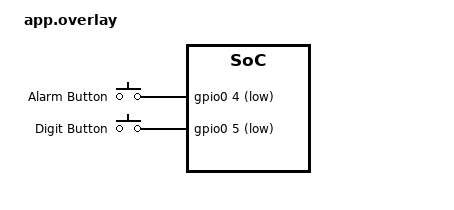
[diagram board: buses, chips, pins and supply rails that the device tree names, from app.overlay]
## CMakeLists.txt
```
# SPDX-License-Identifier: Apache-2.0
cmake_minimum_required(VERSION 3.20.0)

# Define a flag we can pass from the command line (defaults to OFF)
option(BUILD_UNIT_TESTS "Build the host-based unit tests instead of firmware" OFF)

if(BUILD_UNIT_TESTS)
    # ==============================================================
    # HOST UNIT TEST BUILD
    # ==============================================================
    project(display_tests)
    
    # Create a standard desktop executable
    add_executable(unit_test_app 
        test/test_main.c 
        test/mock_os_abstraction.c
        test/mock_display_driver.c
        src/state_manager.c 
        src/display_manager.c
    )
    
    # Point it to your standard headers
    target_include_directories(unit_test_app PRIVATE include)

else()
    # ==============================================================
    # ZEPHYR FIRMWARE BUILD
    # ==============================================================
    find_package(Zephyr REQUIRED HINTS $ENV{ZEPHYR_BASE})
    project(minimal)

    zephyr_include_directories(include)

    target_sources(app PRIVATE 
        src/main.c 
        src/state_manager.c 
        src/display_manager.c 
        src/button_listener.c
        src/zephyr/os_abstraction_zephyr.c
        src/zephyr/zephyr_display_driver.c 
        src/zephyr/zephyr_button_driver.c    
    )
endif()
```

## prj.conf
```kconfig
CONFIG_SAMPLE_DO_OUTPUT=y
CONFIG_SHELL=y
CONFIG_I2C=y
CONFIG_I2C_SHELL=y
CONFIG_I2C_LOG_LEVEL_DBG=y
```

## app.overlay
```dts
/ {
    aliases {
        alarm-button = &button_alarm;
        digit-button = &button_digit;
    };

    gpio_keys {
        compatible = "gpio-keys";
        
        button_alarm: button_alarm {
            /* GPIO 4, enable internal pull-up,
               and treat LOW as logically active */
            gpios = <&gpio0 4 (GPIO_PULL_UP | GPIO_ACTIVE_LOW)>;
            label = "Alarm Button";
        };

        button_digit: button_digit {
            /* GPIO 5, enable internal pull-up,
               and treat LOW as logically active */
            gpios = <&gpio0 5 (GPIO_PULL_UP | GPIO_ACTIVE_LOW)>;
            label = "Digit Button";
        };
    };
};
```

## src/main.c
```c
/*
 * Copyright (c) 2019 Nordic Semiconductor ASA
 *
 * SPDX-License-Identifier: Apache-2.0
 */

#include <stdio.h>
#include <zephyr/kernel.h>
#include "state_manager.h"
#include "display_manager.h"
#include "button_listener.h"
#include "os_abstraction.h"

// The function the OS will call every time the timer expires
void system_tick_callback(void)
{
    StateMsg_t msg;
    msg.event = EVENT_SYS_TICK_MINUTE;
    
    // Drop the event into the queue.
    // (In a real Zephyr/FreeRTOS implementation behind your OSAL, this 
    // underlying queue send needs to have a timeout of 0 / K_NO_WAIT 
    // so it doesn't block the OS timer daemon!)
    rtos_queue_send(state_message_queue, &msg);
}

int main(void)
{
    //Iniitalize message queues here
    printf("Initializing queues.\n");
    state_message_queue = rtos_queue_create(10, sizeof(StateMsg_t));
    display_message_queue = rtos_queue_create(10, sizeof(DisplayMsg_t));
    
    // Create and initialize tasks
    printf("Starting tasks.\n");
    rtos_thread_create(display_manager_task, "DisplayManagerTask",
		       1024, TASK_PRIORITY_MEDIUM);
    rtos_thread_create(button_listener_task, "ButtonListenerTask",
		       1024, TASK_PRIORITY_MEDIUM);
    rtos_thread_create(state_manager_task, "StateManagerTask",
		       1024, TASK_PRIORITY_MEDIUM);

    printf("Setting \"minute change\" timer...\n");    
    // Create a timer that fires every 60,000 ms (1 minute) and repeats (true)
    RtosTimerHandle_t minute_timer = rtos_timer_create(
        "SysTickTimer", 
        60000, 
        true, 
        system_tick_callback
    );
    
    // Start the timer ticking
    rtos_timer_start(minute_timer);    

    // This must be at the end, since it blocks forever
    rtos_start_scheduler();        
    return 0;
}
```

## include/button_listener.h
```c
#ifndef BUTTON_LISTENER_H
#define BUTTON_LISTENER_H

// Button listener task entry point
extern void button_listener_task(void);

#endif // BUTTON_LISTENER_H
```

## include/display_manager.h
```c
#ifndef DISPLAY_MANAGER_H
#define DISPLAY_MANAGER_H

#include <stdint.h>
#include <stdbool.h>

#include "os_abstraction.h"

typedef enum {
    VIEW_STATE_TIME,
    VIEW_STATE_ALARM,
    VIEW_STATE_DIGIT
} DisplayViewState_t;


typedef enum {
    DISPLAY_EVENT_UPDATE_TIME,
    DISPLAY_EVENT_UPDATE_ALARM_STATE,
    DISPLAY_EVENT_SET_ACTIVE_VIEW
} DisplayEvent_t;

// Message structure sent by the higher-level State Manager
typedef struct {
    DisplayEvent_t event;
    union {
        struct { uint8_t hours; uint8_t minutes; } time;
        struct { bool is_set; uint8_t hours; uint8_t minutes; } alarm;
        struct { DisplayViewState_t view; uint8_t digit_val; } view_ctrl;
    } payload;
} DisplayMsg_t;

extern RtosQueueHandle_t display_message_queue;

// Display manager task entry point
extern void initialize_display_manager(void);
extern void display_manager_task();
extern void display_manager_process_event(DisplayMsg_t *);

#endif // DISPLAY_MANAGER_H
```

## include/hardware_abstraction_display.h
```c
#include <stdbool.h>

// Clears the entire dot matrix display
extern void disp_hw_clear(void);

// Writes a formatted string to the dot matrix display (e.g., "12:30", "--:--")
extern void disp_hw_write_text(const char* text);

// Controls the specific hardware pixel in the upper right corner
extern void disp_hw_set_upper_right_dot(bool enable);
```

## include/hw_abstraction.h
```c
#ifndef HW_ABSTRACTION_H
#define HW_ABSTRACTION_H

#include <stdbool.h>
#include "os_abstraction.h"

// Clears the entire dot matrix display
extern void disp_hw_clear(void);

// Writes a formatted string to the dot matrix display (e.g., "12:30", "--:--")
extern void disp_hw_write_text(const char* text);

// Controls the specific hardware pixel in the upper right corner
extern void disp_hw_set_upper_right_dot(bool enable);

// Reads the physical state of the buttons (true = pressed, false = released)
extern RtosSemaphoreHandle_t hw_btn_semaphore_setup(void);
extern bool hw_btn_read_alarm(void);
extern bool hw_btn_read_digit(void);

#endif // HW_ABSTRACTION_H
```

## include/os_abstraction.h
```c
#ifndef OS_ABSTRACTION_H
#define OS_ABSTRACTION_H

#include <stdint.h>
#include <stdbool.h>

#define RTOS_WAIT_FOREVER 0xFFFFFFFF

/*** Time and Timers ***/
// Timer primitives
typedef void* RtosTimerHandle_t;
typedef void (*RtosTimerCallback_t)(void);

// Need to be sure to trigger this callback from a timer
extern void minute_tick_callback(void);

// Returns current system ticks in milliseconds
extern uint32_t rtos_get_time_ms(void);

// RTOS delay (OS sleep, not a busy wait)
extern void rtos_delay_ms(uint32_t ms);


/*** Queues ***/
typedef void* RtosQueueHandle_t;

extern bool rtos_queue_receive(RtosQueueHandle_t queue,
			       void* buffer, uint32_t timeout_ms);
extern bool rtos_queue_send(RtosQueueHandle_t queue, void* data);


/*** Semaphores ***/
typedef void* RtosSemaphoreHandle_t;

extern void rtos_semaphore_wait(RtosSemaphoreHandle_t semaphore,
				uint32_t timeout_ms);


// Initializes all OS primitives (queues, semaphores, timers) and spawns tasks
extern void rtos_system_init(void);

#endif // OS_ABSTRACTION_H
```

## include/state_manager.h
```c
#ifndef STATE_MANAGER_H
#define STATE_MANAGER_H

#include <stdint.h>
#include <stdbool.h>
#include "os_abstraction.h"

// System events generated by the hardware layer (Buttons, Timers) and handled by the state manager
typedef enum {
    EVENT_BUTTON_ALARM_PRESSED,
    EVENT_BUTTON_ALARM_RELEASED,
    EVENT_BUTTON_DIGIT_PRESSED,
    EVENT_BUTTON_DIGIT_RELEASED,
    EVENT_SYS_TICK_MINUTE
} StateEvent_t;

typedef struct {
    StateEvent_t event;
} StateMsg_t;


extern RtosQueueHandle_t state_message_queue;

// Main state manager task entry point
extern void initialize_state_manager(void);
extern void state_manager_task(void);
extern void state_manager_process_event(StateMsg_t *msg);

#endif // STATE_MANAGER_H
```

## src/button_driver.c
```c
#include <stdio.h>
#include "hw_abstraction.h"

bool hw_btn_read_alarm(void)
{
    // Mock implementation
    return false;
}

bool hw_btn_read_digit(void)
{
    // Mock implementation
    return false; 
}
```

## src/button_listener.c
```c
#include <stddef.h>
#include <stdio.h>
#include "button_listener.h"
#include "state_manager.h"
#include "hw_abstraction.h"

void button_listener_task(void)
{
    StateMsg_t msg;
    
    bool last_alarm_state = false;
    bool last_digit_state = false;

    RtosSemaphoreHandle_t hw_btn_isr_semaphore
	= hw_btn_semaphore_setup();
   
    if (hw_btn_isr_semaphore == NULL) {
	printf("Problem setting up button semaphore\n");
	return;
    }

    while (1) {
        // 1. Sleep entirely until the actual hardware ISR gives this semaphore
        rtos_semaphore_wait(hw_btn_isr_semaphore, RTOS_WAIT_FOREVER);

        // 2. Debounce: Wait 20ms for the physical switch contacts to settle
        rtos_delay_ms(20);

        // 3. Read the stable hardware states
        bool current_alarm_state = hw_btn_read_alarm();
        bool current_digit_state = hw_btn_read_digit();

        // 4. Compare to previous state and emit events ONLY on state changes
        if (current_alarm_state != last_alarm_state) {
            msg.event = current_alarm_state ? EVENT_BUTTON_ALARM_PRESSED : EVENT_BUTTON_ALARM_RELEASED;
            rtos_queue_send(state_message_queue, &msg);
            last_alarm_state = current_alarm_state;
        }

        if (current_digit_state != last_digit_state) {
            msg.event = current_digit_state ? EVENT_BUTTON_DIGIT_PRESSED : EVENT_BUTTON_DIGIT_RELEASED;
            rtos_queue_send(state_message_queue, &msg);
            last_digit_state = current_digit_state;
        }
    }
    return;
}
```

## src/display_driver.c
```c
#include <stdio.h>
#include "hw_abstraction.h"

void disp_hw_clear(void)
{
    printf("Calling disp_hw_clear()\n"); 
}

void disp_hw_write_text(const char* text)
{
    printf("Calling disp_hw_write_text(text=\"%s\")\n", text); 
}

void disp_hw_set_upper_right_dot(bool enable)
{
    printf("disp_hw_set_upper_right_dot(enable=\"%s\")\n",
	   enable ? "true" : "false"); 
}
```

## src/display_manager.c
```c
#include <stdio.h>
#include <string.h>
#include "display_manager.h"
#include "os_abstraction.h"
#include "hw_abstraction.h"

static struct {
    DisplayViewState_t current_view;
    
    uint8_t current_hours;
    uint8_t current_minutes;
    
    bool alarm_is_set;
    uint8_t alarm_hours;
    uint8_t alarm_minutes;
    
    uint8_t temp_digit;
} display_manager_context;


// Helper function to render the current state to the hardware
static void render_display(void)
{
    char render_buffer[8]; // Enough to hold "HH:MM" + null terminator
    
    disp_hw_clear();

    switch (display_manager_context.current_view) {
        case VIEW_STATE_TIME:
            snprintf(render_buffer, sizeof(render_buffer), "%02d:%02d",
		     display_manager_context.current_hours, display_manager_context.current_minutes);
            disp_hw_write_text(render_buffer);
            break;

        case VIEW_STATE_ALARM:
            if (display_manager_context.alarm_is_set) {
                snprintf(render_buffer, sizeof(render_buffer), "%02d:%02d",
			 display_manager_context.alarm_hours, display_manager_context.alarm_minutes);
            } else {
                snprintf(render_buffer, sizeof(render_buffer), "--:--");
            }
            disp_hw_write_text(render_buffer);
            break;

        case VIEW_STATE_DIGIT:
            snprintf(render_buffer, sizeof(render_buffer), "%d", display_manager_context.temp_digit);
            disp_hw_write_text(render_buffer);
            break;
    }

    // The alarm indicator dot is persistently rendered regardless of the current view
    disp_hw_set_upper_right_dot(display_manager_context.alarm_is_set);
}

void display_manager_process_event(DisplayMsg_t *msg)
{
    // Process incoming message from higher-level state manager
    switch (msg->event) {
    case DISPLAY_EVENT_UPDATE_TIME:
	display_manager_context.current_hours = msg->payload.time.hours;
	display_manager_context.current_minutes = msg->payload.time.minutes;
	break;

    case DISPLAY_EVENT_UPDATE_ALARM_STATE:
	display_manager_context.alarm_is_set = msg->payload.alarm.is_set;
	display_manager_context.alarm_hours = msg->payload.alarm.hours;
	display_manager_context.alarm_minutes = msg->payload.alarm.minutes;
	break;

    case DISPLAY_EVENT_SET_ACTIVE_VIEW:
	display_manager_context.current_view = msg->payload.view_ctrl.view;
	display_manager_context.temp_digit = msg->payload.view_ctrl.digit_val;
	break;
    }

    render_display();
}

void initialize_display_manager(void)
{
    memset(&display_manager_context, 0, sizeof(display_manager_context));
    display_manager_context.current_view = VIEW_STATE_TIME;
    render_display();
}

void display_manager_task(void)
{
    DisplayMsg_t msg;

    // Initialize state
    initialize_display_manager();
    
    while (1) {
        // Wait indefinitely for a message.
        if (rtos_queue_receive(display_message_queue, &msg, RTOS_WAIT_FOREVER)) {
            display_manager_process_event(&msg);
	}
    }
}
```

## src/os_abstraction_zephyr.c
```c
#include <stdio.h>
#include <zephyr/kernel.h>
#include "os_abstraction.h"
#include "state_manager.h"
#include "display_manager.h"
#include "button_listener.h"

/* ========================================================================= *
 * Static Allocations (Zephyr Macros)
 * ========================================================================= */

// 1. Queues
K_MSGQ_DEFINE(z_state_msgq, sizeof(StateMsg_t), 10, 4);
K_MSGQ_DEFINE(z_display_msgq, sizeof(DisplayMsg_t), 10, 4);

// Map the static Zephyr objects to the abstract global handles expected by the app
RtosQueueHandle_t state_message_queue = &z_state_msgq;

RtosQueueHandle_t display_message_queue = &z_display_msgq;

// 2. Threads (Auto-started by Zephyr before main)
// K_THREAD_DEFINE(name, stack_size, entry_fn, p1, p2, p3, prio, options, delay)
K_THREAD_DEFINE(display_tid, 1024, display_manager_task, NULL, NULL, NULL, 5, 0, 0);
K_THREAD_DEFINE(button_tid,  1024, button_listener_task, NULL, NULL, NULL, 5, 0, 0);
K_THREAD_DEFINE(state_tid,   1024, state_manager_task,   NULL, NULL, NULL, 5, 0, 0);

// 3. System Timer
extern void minute_tick_callback(void); // Declared in main.c
K_TIMER_DEFINE(z_sys_timer, (k_timer_expiry_t)minute_tick_callback, NULL);


/* ========================================================================= *
 * Initialization and Scheduler
 * ========================================================================= */

void rtos_system_init(void)
{
    printf("OSAL: Starting system timer...\n");
    // Start the static timer (60 seconds duration, 60 seconds period)
    k_timer_start(&z_sys_timer, K_MSEC(60000), K_MSEC(60000));

    k_sleep(K_FOREVER);
}

/* ========================================================================= *
 * OS API Implementations
 * ========================================================================= */

uint32_t rtos_get_time_ms(void) {
    return k_uptime_get_32();
}

void rtos_delay_ms(uint32_t ms) {
    k_msleep(ms);
}

bool rtos_queue_receive(RtosQueueHandle_t queue, void* buffer, uint32_t timeout_ms) {
    struct k_msgq *q = (struct k_msgq *)queue;
    k_timeout_t z_timeout = (timeout_ms == RTOS_WAIT_FOREVER) ? K_FOREVER : K_MSEC(timeout_ms);
    return (k_msgq_get(q, buffer, z_timeout) == 0);
}

bool rtos_queue_send(RtosQueueHandle_t queue, void* data) {
    struct k_msgq *q = (struct k_msgq *)queue;
    return (k_msgq_put(q, data, K_NO_WAIT) == 0);
}

void rtos_semaphore_wait(RtosSemaphoreHandle_t semaphore, uint32_t timeout_ms) {
    struct k_sem *sem = (struct k_sem *)semaphore;
    k_timeout_t z_timeout = (timeout_ms == RTOS_WAIT_FOREVER) ? K_FOREVER : K_MSEC(timeout_ms);
    k_sem_take(sem, z_timeout);
}
```

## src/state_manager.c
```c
#include "state_manager.h"
#include "display_manager.h"

static struct {
    bool btn_alarm_active;
    bool btn_digit_active;
    DisplayViewState_t current_view;
    
    uint8_t sys_hours;
    uint8_t sys_minutes;
    uint8_t alarm_hours;
    uint8_t alarm_minutes;
    bool alarm_enabled;
    uint8_t display_digit; 
} sm_ctx;

static void initialize_sm_ctx(void)
{
    // Internal state tracking
    sm_ctx.btn_alarm_active = false;
    sm_ctx.btn_digit_active = false;
    sm_ctx.current_view = VIEW_STATE_TIME;

    // Dummy system data
    sm_ctx.sys_hours = 12;
    sm_ctx.sys_minutes = 0;
    sm_ctx.alarm_hours = 6;
    sm_ctx.alarm_minutes = 30;
    sm_ctx.alarm_enabled = true;
    sm_ctx.display_digit = 8; 
}

static void initialize_display(RtosQueueHandle_t queue)
{
    // Initial push to the display
    DisplayMsg_t init_msg;
    init_msg.event = DISPLAY_EVENT_UPDATE_TIME;
    init_msg.payload.time.hours = sm_ctx.sys_hours;
    init_msg.payload.time.minutes = sm_ctx.sys_minutes;
    rtos_queue_send(queue, &init_msg);

    init_msg.event = DISPLAY_EVENT_UPDATE_ALARM_STATE;
    init_msg.payload.alarm.is_set = sm_ctx.alarm_enabled;
    init_msg.payload.alarm.hours = sm_ctx.alarm_hours;
    init_msg.payload.alarm.minutes = sm_ctx.alarm_minutes;
    rtos_queue_send(queue, &init_msg);


}

// The function the OS will call every time the timer expires
void minute_tick_callback(void)
{
    StateMsg_t msg;
    msg.event = EVENT_SYS_TICK_MINUTE;
    
    // Drop the event into the queue.
    // (In a real Zephyr/FreeRTOS implementation behind your OSAL, this 
    // underlying queue send needs to have a timeout of 0 / K_NO_WAIT 
    // so it doesn't block the OS timer daemon!)
    rtos_queue_send(state_message_queue, &msg);
}

void state_manager_process_event(StateMsg_t *msg)
{
    DisplayViewState_t target_view = sm_ctx.current_view;

    // 1. Process the incoming event
    switch (msg->event) {
        case EVENT_BUTTON_ALARM_PRESSED:
            sm_ctx.btn_alarm_active = true;
	    target_view = VIEW_STATE_ALARM;
            break;
        case EVENT_BUTTON_ALARM_RELEASED:
            sm_ctx.btn_alarm_active = false;
	    if (target_view == VIEW_STATE_ALARM) {
		target_view = (sm_ctx.btn_digit_active ?
			       VIEW_STATE_DIGIT :
			       VIEW_STATE_TIME);
	    }
            break;
        case EVENT_BUTTON_DIGIT_PRESSED:
            sm_ctx.btn_digit_active = true;
	    target_view = VIEW_STATE_DIGIT;
            break;
        case EVENT_BUTTON_DIGIT_RELEASED:
            sm_ctx.btn_digit_active = false;
	    if (target_view == VIEW_STATE_DIGIT) {
		target_view = (sm_ctx.btn_alarm_active ?
			       VIEW_STATE_ALARM :
			       VIEW_STATE_TIME);
	    }
            break;
        case EVENT_SYS_TICK_MINUTE:
            sm_ctx.sys_minutes++;
            if (sm_ctx.sys_minutes >= 60) {
                sm_ctx.sys_minutes = 0;
                sm_ctx.sys_hours = (sm_ctx.sys_hours + 1) % 24;
            }                    
            DisplayMsg_t time_msg = { .event = DISPLAY_EVENT_UPDATE_TIME };
            time_msg.payload.time.hours = sm_ctx.sys_hours;
            time_msg.payload.time.minutes = sm_ctx.sys_minutes;
            rtos_queue_send(display_message_queue, &time_msg);
            break;
    }
    if (target_view != sm_ctx.current_view) {
	sm_ctx.current_view = target_view;
	DisplayMsg_t view_msg = { .event = DISPLAY_EVENT_SET_ACTIVE_VIEW };
	view_msg.payload.view_ctrl.view = target_view;
	view_msg.payload.view_ctrl.digit_val = sm_ctx.display_digit;
	rtos_queue_send(display_message_queue, &view_msg);
    }
}

void initialize_state_manager(void)
{
    initialize_sm_ctx();

    initialize_display(display_message_queue);
}

void state_manager_task(void)
{
    StateMsg_t msg;

    initialize_state_manager();
    
    while (1) {
        // Wait for an event from the button listener or system timer
        if (rtos_queue_receive(state_message_queue, &msg, RTOS_WAIT_FOREVER)) {
	    state_manager_process_event(&msg);
        }
    }
}
```
